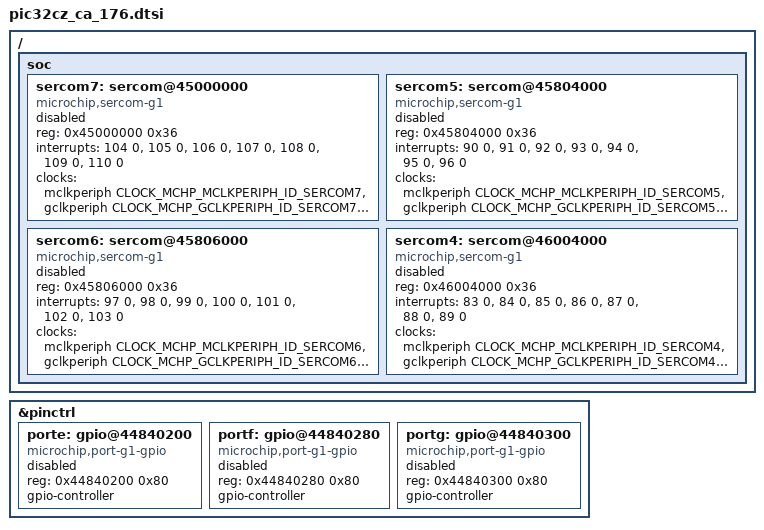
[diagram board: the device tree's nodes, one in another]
/*
 * Copyright (c) 2025-2026 Microchip Technology Inc.
 *
 * SPDX-License-Identifier: Apache-2.0
 */

#include <microchip/pic32c/pic32cz_ca/common/pic32cz_ca.dtsi>

/ {
	soc {
		sercom7: sercom@45000000 {
			compatible = "microchip,sercom-g1";
			reg = <0x45000000 0x36>;
			interrupts = <104 0>, <105 0>, <106 0>, <107 0>, <108 0>, <109 0>, <110 0>;
			interrupt-names = "error", "rxbrk", "dre", "txc", "rxc", "rxs", "ctsic";
			clocks = <&mclkperiph CLOCK_MCHP_MCLKPERIPH_ID_SERCOM7>,
				 <&gclkperiph CLOCK_MCHP_GCLKPERIPH_ID_SERCOM7_CORE>;
			clock-names = "mclk", "gclk";
			status = "disabled";
		};

		sercom5: sercom@45804000 {
			compatible = "microchip,sercom-g1";
			reg = <0x45804000 0x36>;
			interrupts = <90 0>, <91 0>, <92 0>, <93 0>, <94 0>, <95 0>, <96 0>;
			interrupt-names = "error", "rxbrk", "dre", "txc", "rxc", "rxs", "ctsic";
			clocks = <&mclkperiph CLOCK_MCHP_MCLKPERIPH_ID_SERCOM5>,
				 <&gclkperiph CLOCK_MCHP_GCLKPERIPH_ID_SERCOM5_CORE>;
			clock-names = "mclk", "gclk";
			status = "disabled";
		};

		sercom6: sercom@45806000 {
			compatible = "microchip,sercom-g1";
			reg = <0x45806000 0x36>;
			interrupts = <97 0>, <98 0>, <99 0>, <100 0>, <101 0>, <102 0>, <103 0>;
			interrupt-names = "error", "rxbrk", "dre", "txc", "rxc", "rxs", "ctsic";
			clocks = <&mclkperiph CLOCK_MCHP_MCLKPERIPH_ID_SERCOM6>,
				 <&gclkperiph CLOCK_MCHP_GCLKPERIPH_ID_SERCOM6_CORE>;
			clock-names = "mclk", "gclk";
			status = "disabled";
		};

		sercom4: sercom@46004000 {
			compatible = "microchip,sercom-g1";
			reg = <0x46004000 0x36>;
			interrupts = <83 0>, <84 0>, <85 0>, <86 0>, <87 0>, <88 0>, <89 0>;
			interrupt-names = "error", "rxbrk", "dre", "txc", "rxc", "rxs", "ctsic";
			clocks = <&mclkperiph CLOCK_MCHP_MCLKPERIPH_ID_SERCOM4>,
				 <&gclkperiph CLOCK_MCHP_GCLKPERIPH_ID_SERCOM4_CORE>;
			clock-names = "mclk", "gclk";
			status = "disabled";
		};
	};
};

&pinctrl {
	porte: gpio@44840200 {
		compatible = "microchip,port-g1-gpio";
		reg = <0x44840200 0x80>;
		gpio-controller;
		#gpio-cells = <2>;
		#microchip,pin-cells = <2>;
		status = "disabled";
	};

	portf: gpio@44840280 {
		compatible = "microchip,port-g1-gpio";
		reg = <0x44840280 0x80>;
		gpio-controller;
		#gpio-cells = <2>;
		#microchip,pin-cells = <2>;
		status = "disabled";
	};

	portg: gpio@44840300 {
		compatible = "microchip,port-g1-gpio";
		reg = <0x44840300 0x80>;
		gpio-controller;
		#gpio-cells = <2>;
		#microchip,pin-cells = <2>;
		status = "disabled";
	};
};
